# ESP32-H4 register map
Vendor: ESPRESSIF SYSTEMS (SHANGHAI) CO., LTD.; Series: ESP32 H-Series; File version: 1
CPU: RV32IMAC r0p0, little endian, no MPU, no FPU, 0 interrupt priority bits
Address unit: 32 bits
Registers are 32-bit, read-write, reset 0x0 unless marked. A register's access mark holds for its fields unless they carry their own. Offsets are from the block's base; [hi:lo] are bit positions; {n}, {i} and the like mark numbered series; <NAME> marks a mode.

## SPI2 — SPI (Serial Peripheral Interface) Controller 2
Base 0x60010000
Same registers: SPI3 0x60011000
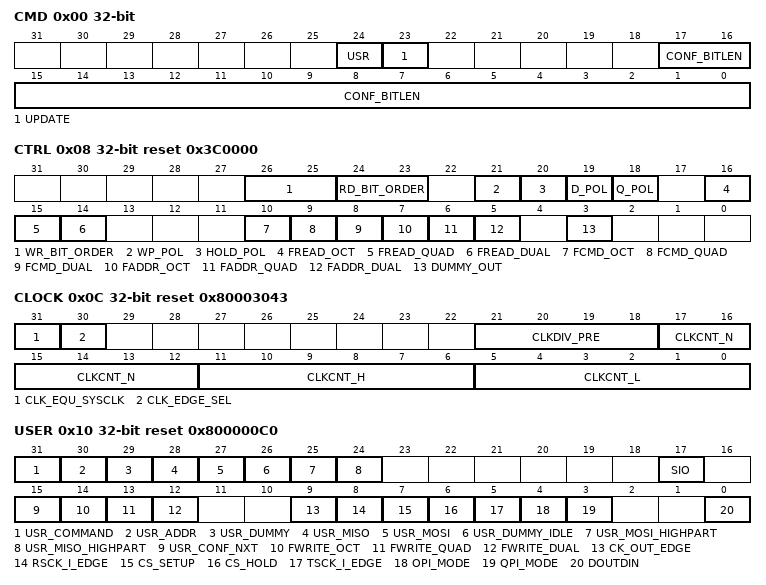
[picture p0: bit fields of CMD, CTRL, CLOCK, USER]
0x00 CMD — Command control register
  [24] USR — Configures whether or not to enable user-defined command. \\ 0: Not enable \\ 1: Enable \\ An SPI operation will be triggered when the bit is set. This bit will be cleared once the operation is done. Can not be changed by CONF_buf.
  [23] UPDATE — Configures whether or not to synchronize SPI registers from APB clock domain into SPI module clock domain. \\ 0: Not synchronize \\ 1: Synchronize \\ This bit is only used in SPI master transfer.
  [17:0] CONF_BITLEN — Configures the SPI_CLK cycles of SPI CONF state. Measurement unit: SPI_CLK clock cycle.\\ Can be configured in CONF state.
0x04 ADDR — Address value register
  [31:0] USR_ADDR_VALUE — Configures the address to slave. Can be configured in CONF state.
0x08 CTRL access per field reset 0x3C0000 — SPI control register
  [26:25] WR_BIT_ORDER rw — Configures the bit order in command (CMD), address (ADDR), and write-data (MOSI) states. \\ 0: MSB first \\ 1: LSB first \\ Can be configured in CONF state.
  [24:23] RD_BIT_ORDER rw — Configures the bit order in read-data (MISO) state. \\ 0: MSB first \\ 1: LSB first \\ Can be configured in CONF state.
  [21] WP_POL rw — Configures the output value of write-protect signal when SPI is in idle. \\ 0: Output low \\ 1: Output high \\ Can be configured in CONF state.
  [20] HOLD_POL rw — Configures SPI_HOLD output value when SPI is in idle. \\ 0: Output low \\ 1: Output high \\ Can be configured in CONF state.
  [19] D_POL rw — Configures MOSI line polarity. \\ 0: Low \\ 1: High \\ Can be configured in CONF state.
  [18] Q_POL rw — Configures MISO line polarity. \\ 0: Low \\ 1: High \\ Can be configured in CONF state.
  [16] FREAD_OCT ro — Configures whether or not to enable the 8-bit mode of read-data (DIN) state in read operations. \\ 0: Disable \\ 1: Enable \\ Can be configured in CONF state.
  [15] FREAD_QUAD rw — Configures whether or not to enable the 4-bit mode of read-data (DIN) state in read operations. \\ 0: Disable \\ 1: Enable \\ Can be configured in CONF state.
  [14] FREAD_DUAL rw — Configures whether or not to enable the 2-bit mode of read-data (DIN) state in read operations. \\ 0: Disable \\ 1: Enable \\ Can be configured in CONF state.
  [10] FCMD_OCT ro — Configures whether or not to enable 8-bit mode during command (CMD) state. \\ 0: Disable \\ 1: Enable \\ Can be configured in CONF state.
  [9] FCMD_QUAD rw — Configures whether or not to enable 4-bit mode during command (CMD) state. \\ 0: Disable \\ 1: Enable \\ Can be configured in CONF state.
  [8] FCMD_DUAL rw — Configures whether or not to enable 2-bit mode during command (CMD) state. \\ 0: Disable \\ 1: Enable \\ Can be configured in CONF state.
  [7] FADDR_OCT ro — Configures whether or not to enable 8-bit mode during address (ADDR) state. \\ 0: Disable \\ 1: Enable \\ Can be configured in CONF state.
  [6] FADDR_QUAD rw — Configures whether or not to enable 4-bit mode during address (ADDR) state. \\ 0: Disable \\ 1: Enable \\ Can be configured in CONF state.
  [5] FADDR_DUAL rw — Configures whether or not to enable 2-bit mode during address (ADDR) state.\\ 0: Disable \\ 1: Enable \\ Can be configured in CONF state.
  [3] DUMMY_OUT rw — Configures whether or not to output the FSPI bus signals in DUMMY state. \\ 0: Not output \\ 1: Output \\ Can be configured in CONF state.
0x0C CLOCK reset 0x80003043 — SPI clock control register
  [31] CLK_EQU_SYSCLK — Configures whether or not the SPI_CLK is equal to APB_CLK in master transfer.\\ 0: SPI_CLK is divided from APB_CLK.\\ 1: SPI_CLK is eqaul to APB_CLK.\\ Can be configured in CONF state.
  [30] CLK_EDGE_SEL — Configures use standard clock sampling edge or delay the sampling edge by half a cycle in master transfer.\\ 0: clock sampling edge is delayed by half a cycle.\\ 1: clock sampling edge is standard.\\ Can be configured in CONF state.
  [21:18] CLKDIV_PRE — Configures the pre-divider of SPI_CLK in master transfer. Can be configured in CONF state.
  [17:12] CLKCNT_N — Configures the divider of SPI_CLK in master transfer. SPI_CLK frequency is 12_{ extrm{apb_clk}}$/(SPI_CLKDIV_PRE + 1)/(SPI_CLKCNT_N + 1). \\ Can be configured in CONF state.
  [11:6] CLKCNT_H — Configures the duty cycle of SPI_CLK (high level) in master transfer. It's recommended to configure this value to floor((SPI_CLKCNT_N + 1)/2 - 1). floor() here is to round a number down, e.g., floor(2.2) = 2. In slave mode, it must be 0. \\ Can be configured in CONF state.
  [5:0] CLKCNT_L — In master transfer, this field must be equal to SPI_CLKCNT_N. In slave mode, it must be 0. Can be configured in CONF state.
0x10 USER access per field reset 0x800000C0 — SPI USER control register
  [31] USR_COMMAND rw — Configures whether or not to enable the command (CMD) state of an operation. \\ 0: Disable \\ 1: Enable \\ Can be configured in CONF state.
  [30] USR_ADDR rw — Configures whether or not to enable the address (ADDR) state of an operation. \\ 0: Disable \\ 1: Enable \\ Can be configured in CONF state.
  [29] USR_DUMMY rw — Configures whether or not to enable the DUMMY state of an operation. \\ 0: Disable \\ 1: Enable \\ Can be configured in CONF state.
  [28] USR_MISO rw — Configures whether or not to enable the read-data (DIN) state of an operation. \\ 0: Disable \\ 1: Enable \\ Can be configured in CONF state.
  [27] USR_MOSI rw — Configures whether or not to enable the write-data (DOUT) state of an operation. \\ 0: Disable \\ 1: Enable \\ Can be configured in CONF state.
  [26] USR_DUMMY_IDLE rw — Configures whether or not to disable SPI clock in DUMMY state. \\ 0: Not disable \\ 1: Disable \\ Can be configured in CONF state.
  [25] USR_MOSI_HIGHPART rw — Configures whether or not to enable high part mode, i.e., only access to high part of the buffers: SPI_W8_REG ~ SPI_W15_REG in write-data phase. \\ 0: Disable \\ 1: Enable \\ Can be configured in CONF state.
  [24] USR_MISO_HIGHPART rw — Configures whether or not to enable high part mode, i.e., only access to high part of the buffers: SPI_W8_REG ~ SPI_W15_REG in read-data phase. \\ 0: Disable \\ 1: Enable \\ Can be configured in CONF state.
  [17] SIO rw — Configures whether or not to enable 3-line half-duplex communication, where MOSI and MISO signals share the same pin.\\ 0: Disable \\ 1: Enable \\ Can be configured in CONF state.
  [15] USR_CONF_NXT rw — Configures whether or not to enable the CONF state for the next transaction (segment) in a configurable segmented transfer. \\ 0: this transfer will end after the current transaction (segment) is finished. Or this is not a configurable segmented transfer. \\ 1: this configurable segmented transfer will continue its next transaction (segment). \\ Can be configured in CONF state.
  [14] FWRITE_OCT ro — In the write operations read-data phase apply 8 signals. Can be configured in CONF state.
  [13] FWRITE_QUAD rw — Configures whether or not to enable the 4-bit mode of read-data phase in write operations. \\ 0: Not enable \\ 1: Enable \\ Can be configured in CONF state.
  [12] FWRITE_DUAL rw — Configures whether or not to enable the 2-bit mode of read-data phase in write operations.\\ 0: Not enable \\ 1: Enable \\ Can be configured in CONF state.
  [9] CK_OUT_EDGE rw — Configures SPI clock mode together with SPI_CK_IDLE_EDGE. Can be configured in CONF state. For more information, see Section <a href='GP-SPI2 master clock control'>link</a>.
  [8] RSCK_I_EDGE rw — Configures whether or not to change the polarity of RSCK in slave transfer. \\ 0: RSCK = !SPI_CK_I \\ 1: RSCK = SPI_CK_I \\
  [7] CS_SETUP rw — Configures whether or not to enable SPI CS when SPI is in prepare (PREP) state. \\ 0: Disable \\ 1: Enable \\ Can be configured in CONF state.
  [6] CS_HOLD rw — Configures whether or not to keep SPI CS low when SPI is in DONE state. \\ 0: Not keep low \\ 1: Keep low \\ Can be configured in CONF state.
  [5] TSCK_I_EDGE rw — Configures whether or not to change the polarity of TSCK in slave transfer. \\ 0: TSCK = SPI_CK_I \\ 1: TSCK = !SPI_CK_I \\
  [4] OPI_MODE ro — Just for master mode. 1: spi controller is in OPI mode (all in 8-b-m). 0: others. Can be configured in CONF state.
  [3] QPI_MODE rw — Configures whether or not to enable QPI mode. \\ 0: Disable \\ 1: Enable \\ This configuration is applicable when the SPI controller works as master or slave. Can be configured in CONF state.
  [0] DOUTDIN rw — Configures whether or not to enable full-duplex communication. \\ 0: Disable \\ 1: Enable \\ Can be configured in CONF state.
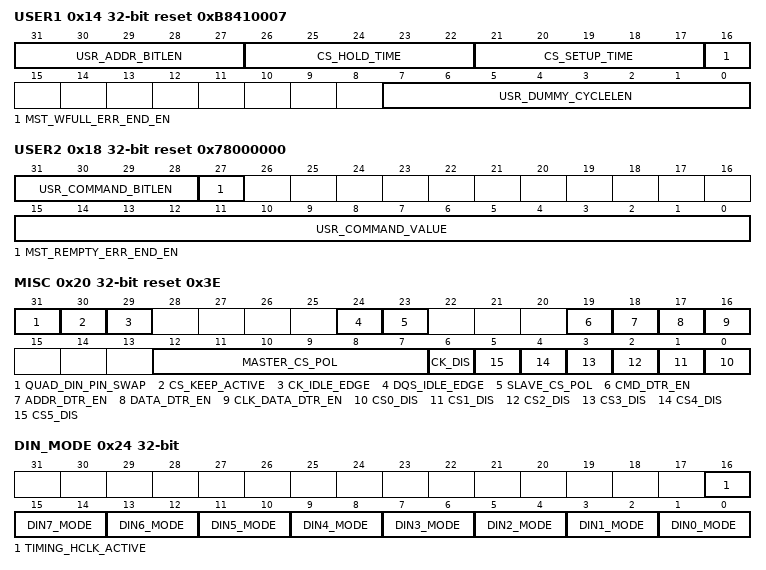
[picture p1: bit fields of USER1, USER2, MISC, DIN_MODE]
0x14 USER1 reset 0xB8410007 — SPI USER control register 1
  [31:27] USR_ADDR_BITLEN — Configures the bit length in address state. This value is (expected bit number - 1). Can be configured in CONF state.
  [26:22] CS_HOLD_TIME — Configures the delay cycles of CS pin. Measurement unit: SPI_CLK clock cycles. \\ This field is used together with SPI_CS_HOLD. Can be configured in CONF state.
  [21:17] CS_SETUP_TIME — Configures the length of prepare (PREP) state. Measurement unit: SPI_CLK clock cycles.\\ This value is equal to the expected cycles - 1. This field is used together with SPI_CS_SETUP. Can be configured in CONF state.
  [16] MST_WFULL_ERR_END_EN — Configures whether or not to end the SPI transfer when SPI RX AFIFO wfull error occurs in master full-/half-duplex transfers. \\ 0: Not end \\ 1: End \\
  [7:0] USR_DUMMY_CYCLELEN — Configures the length of DUMMY state. Measurement unit: SPI_CLK clock cycles.\\ This value is (the expected cycle number - 1). Can be configured in CONF state.
0x18 USER2 reset 0x78000000 — SPI USER control register 2
  [31:28] USR_COMMAND_BITLEN — Configures the bit length of command state. This value is (expected bit number - 1). Can be configured in CONF state.
  [27] MST_REMPTY_ERR_END_EN — Configures whether or not to end the SPI transfer when SPI TX AFIFO read empty error occurs in master full-/half-duplex transfers. \\ 0: Not end \\ 1: End \\
  [15:0] USR_COMMAND_VALUE — Configures the command value. Can be configured in CONF state.
0x1C MS_DLEN — SPI data bit length control register
  [17:0] MS_DATA_BITLEN — Configures the data bit length of SPI transfer in DMA-controlled master transfer or in CPU-controlled master transfer. Or configures the bit length of SPI RX transfer in DMA-controlled slave transfer. This value shall be (expected bit_num - 1). Can be configured in CONF state.
0x20 MISC access per field reset 0x3E — SPI misc register
  [31] QUAD_DIN_PIN_SWAP rw — 1: SPI quad input swap enable, swap FSPID with FSPIQ, swap FSPIWP with FSPIHD. 0: spi quad input swap disable. Can be configured in CONF state.
  [30] CS_KEEP_ACTIVE rw — Configures whether or not to keep the SPI_CS line low.\\ 0: Not keep low\\ 1: Keep low\\ Can be configured in CONF state.
  [29] CK_IDLE_EDGE rw — Configures the level of SPI_CLK line when GP-SPI2 is in idle.\\ 0: Low\\ 1: High\\ Can be configured in CONF state.
  [24] DQS_IDLE_EDGE ro — The default value of spi_dqs. Can be configured in CONF state.
  [23] SLAVE_CS_POL rw — Configures whether or not invert SPI slave input CS polarity.\\ 0: Not change\\ 1: Invert\\ Can be configured in CONF state.
  [19] CMD_DTR_EN ro — 1: SPI clk and data of SPI_SEND_CMD state are in DTR mode, including master 1/2/4/8-bm. 0: SPI clk and data of SPI_SEND_CMD state are in STR mode. Can be configured in CONF state.
  [18] ADDR_DTR_EN ro — 1: SPI clk and data of SPI_SEND_ADDR state are in DTR mode, including master 1/2/4/8-bm. 0: SPI clk and data of SPI_SEND_ADDR state are in STR mode. Can be configured in CONF state.
  [17] DATA_DTR_EN ro — 1: SPI clk and data of SPI_DOUT and SPI_DIN state are in DTR mode, including master 1/2/4/8-bm. 0: SPI clk and data of SPI_DOUT and SPI_DIN state are in STR mode. Can be configured in CONF state.
  [16] CLK_DATA_DTR_EN ro — 1: SPI master DTR mode is applied to SPI clk, data and spi_dqs. 0: SPI master DTR mode is only applied to spi_dqs. This bit should be used with bit 17/18/19.
  [12:7] MASTER_CS_POL rw — Configures the polarity of SPI_CS7 (7 = 0-5) line in master transfer.\\ 0: SPI_CS7 is low active.\\ 1: SPI_CS7 is high active.\\ Can be configured in CONF state.
  [6] CK_DIS rw — Configures whether or not to disable SPI_CLK output.\\ 0: Enable\\ 1: Disable\\ Can be configured in CONF state.
  [n] CS{n}_DIS rw (n=0..5) — Configures whether or not to disable SPI_CS{n} pin.\\ 0: SPI_CS{n} signal is from/to SPI_CS{n} pin.\\ 1: Disable SPI_CS{n} pin.\\ Can be configured in CONF state.
0x24 DIN_MODE access per field — SPI input delay mode configuration
  [16] TIMING_HCLK_ACTIVE rw — Configures whether or not to enable HCLK (high-frequency clock) in SPI input timing module.\\ 0: Disable\\ 1: Enable\\ Can be configured in CONF state.
  [2n+1:2n] DIN{n}_MODE ro (n=4..7) — the input signals are delayed by SPI module clock cycles, 0: input without delayed, 1: input with the posedge of clk_apb,2 input with the negedge of clk_apb, 3: input with the spi_clk. Can be configured in CONF state.
  [7:6] DIN3_MODE rw — Configures the input mode for FSPIHD signal.\\ 0: Input without delay\\ 1: Input at the (SPI_DIN3_NUM + 1)th falling edge of clk_spi_mst\\ 2: Input at the (SPI_DIN3_NUM + 1)th rising edge of clk_hclk plus one clk_spi_mst rising edge cycle\\ 3: Input at the (SPI_DIN3_NUM + 1)th rising edge of clk_hclk plus one clk_spi_mst falling edge cycle\\ Can be configured in CONF state.
  [5:4] DIN2_MODE rw — Configures the input mode for FSPIWP signal.\\ 0: Input without delay\\ 1: Input at the (SPI_DIN2_NUM + 1)th falling edge of clk_spi_mst\\ 2: Input at the (SPI_DIN2_NUM + 1)th rising edge of clk_hclk plus one clk_spi_mst rising edge cycle\\ 3: Input at the (SPI_DIN2_NUM + 1)th rising edge of clk_hclk plus one clk_spi_mst falling edge cycle\\ Can be configured in CONF state.
  [3:2] DIN1_MODE rw — Configures the input mode for FSPIQ signal.\\ 0: Input without delay\\ 1: Input at the (SPI_DIN1_NUM+1)th falling edge of clk_spi_mst\\ 2: Input at the (SPI_DIN1_NUM + 1)th rising edge of clk_hclk plus one clk_spi_mst rising edge cycle\\ 3: Input at the (SPI_DIN1_NUM + 1)th rising edge of clk_hclk plus one clk_spi_mst falling edge cycle\\ Can be configured in CONF state.
  [1:0] DIN0_MODE rw — Configures the input mode for FSPID signal.\\ 0: Input without delay\\ 1: Input at the (SPI_DIN0_NUM + 1)th falling edge of clk_spi_mst\\ 2: Input at the (SPI_DIN0_NUM + 1)th rising edge of clk_hclk plus one clk_spi_mst rising edge cycle\\ 3: Input at the (SPI_DIN0_NUM + 1)th rising edge of clk_hclk plus one clk_spi_mst falling edge cycle\\ Can be configured in CONF state.
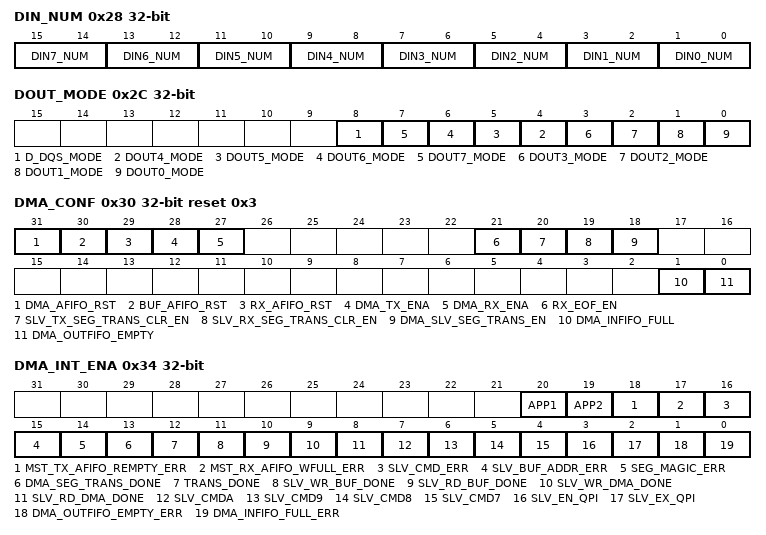
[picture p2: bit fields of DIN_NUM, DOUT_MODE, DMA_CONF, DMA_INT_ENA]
0x28 DIN_NUM access per field — SPI input delay number configuration
  [2n+1:2n] DIN{n}_NUM ro (n=4..7) — the input signals are delayed by SPI module clock cycles, 0: delayed by 1 cycle, 1: delayed by 2 cycles,... Can be configured in CONF state.
  [7:6] DIN3_NUM rw — Configures the delays to input signal FSPIHD based on the setting of SPI_DIN3_MODE.\\ 0: Delayed by 1 clock cycle\\ 1: Delayed by 2 clock cycles\\ 2: Delayed by 3 clock cycles\\ 3: Delayed by 4 clock cycles\\ Can be configured in CONF state.
  [5:4] DIN2_NUM rw — Configures the delays to input signal FSPIWP based on the setting of SPI_DIN2_MODE.\\ 0: Delayed by 1 clock cycle\\ 1: Delayed by 2 clock cycles\\ 2: Delayed by 3 clock cycles\\ 3: Delayed by 4 clock cycles\\ Can be configured in CONF state.
  [3:2] DIN1_NUM rw — Configures the delays to input signal FSPIQ based on the setting of SPI_DIN1_MODE.\\ 0: Delayed by 1 clock cycle\\ 1: Delayed by 2 clock cycles\\ 2: Delayed by 3 clock cycles\\ 3: Delayed by 4 clock cycles\\ Can be configured in CONF state.
  [1:0] DIN0_NUM rw — Configures the delays to input signal FSPID based on the setting of SPI_DIN0_MODE.\\ 0: Delayed by 1 clock cycle\\ 1: Delayed by 2 clock cycles\\ 2: Delayed by 3 clock cycles\\ 3: Delayed by 4 clock cycles\\ Can be configured in CONF state.
0x2C DOUT_MODE access per field — SPI output delay mode configuration
  [8] D_DQS_MODE ro — The output signal SPI_DQS is delayed by the SPI module clock, 0: output without delayed, 1: output delay for a SPI module clock cycle at its negative edge. Can be configured in CONF state.
  [n] DOUT{n}_MODE ro (n=4..7) — The output signal {n} is delayed by the SPI module clock, 0: output without delayed, 1: output delay for a SPI module clock cycle at its negative edge. Can be configured in CONF state.
  [3] DOUT3_MODE rw — Configures the output mode for FSPIHD signal.\\ 0: Output without delay\\ 1: Output with a delay of a SPI module clock cycle at its falling edge\\ Can be configured in CONF state.
  [2] DOUT2_MODE rw — Configures the output mode for FSPIWP signal.\\ 0: Output without delay\\ 1: Output with a delay of a SPI module clock cycle at its falling edge\\ Can be configured in CONF state.
  [1] DOUT1_MODE rw — Configures the output mode for FSPIQ signal.\\ 0: Output without delay\\ 1: Output with a delay of a SPI module clock cycle at its falling edge\\ Can be configured in CONF state.
  [0] DOUT0_MODE rw — Configures the output mode for FSPID signal.\\ 0: Output without delay\\ 1: Output with a delay of a SPI module clock cycle at its falling edge\\ Can be configured in CONF state.
0x30 DMA_CONF access per field reset 0x3 — SPI DMA control register
  [31] DMA_AFIFO_RST wo — Configures whether or not to reset dma_tx_afifo as shown in Figure <a href='fig:spi-master-data-flow-control'>link</a> and in Figure <a href='fig:spi-slave-data-flow-control'>link</a>.\\ 0: Not reset\\ 1: Reset\\ dma_tx_afifo is used to send data out in DMA-controlled slave transfer.
  [30] BUF_AFIFO_RST wo — Configures whether or not to reset buf_tx_afifo as shown in Figure <a href='fig:spi-master-data-flow-control'>link</a> and in Figure <a href='fig:spi-slave-data-flow-control'>link</a>.\\ 0: Not reset\\ 1: Reset\\ buf_tx_afifo is used to send data out in CPU-controlled master and slave transfer.
  [29] RX_AFIFO_RST wo — Configures whether or not to reset spi_rx_afifo as shown in Figure <a href='fig:spi-master-data-flow-control'>link</a> and in Figure <a href='fig:spi-slave-data-flow-control'>link</a>.\\ 0: Not reset\\ 1: Reset\\ spi_rx_afifo is used to receive data in SPI master and slave transfer.
  [28] DMA_TX_ENA rw — Configures whether or not to enable DMA-controlled send data transfer.\\ 0: Disable\\ 1: Enable\\
  [27] DMA_RX_ENA rw — Configures whether or not to enable DMA-controlled receive data transfer.\\ 0: Disable\\ 1: Enable\\
  [21] RX_EOF_EN rw — 1: In a DAM-controlled transfer, if the bit number of transferred data is equal to (SPI_MS_DATA_BITLEN + 1), then GDMA_IN_SUC_EOF_CH\it{n}_INT_RAW will be set by hardware. 0: GDMA_IN_SUC_EOF_CH\it{n}_INT_RAW is set by SPI_TRANS_DONE_INT event in a single transfer, or by an SPI_DMA_SEG_TRANS_DONE_INT event in a segmented transfer.
  [20] SLV_TX_SEG_TRANS_CLR_EN rw — In slave segmented transfer, if the size of the DMA TX buffer is smaller than the size of the transmitted data,\\ 1: the data in the following transactions will not be updated, i.e. the old data is transmitted repeatedly.\\ 0: the data in this transaction will not be updated. But in the following transactions,\\ - if new data is filled in DMA TX FIFO, new data will be transmitted. - if no new data is filled in DMA TX FIFO, no new data will be transmitted.
  [19] SLV_RX_SEG_TRANS_CLR_EN rw — In slave segmented transfer, if the size of the DMA RX buffer is smaller than the size of the received data, \\1: the data in all the following Wr_DMA transactions will not be received\\ 0: the data in this Wr_DMA transaction will not be received, but in the following transactions,\\ - if the size of DMA RX buffer is not 0, the data in following Wr_DMA transactions will be received. - if the size of DMA RX buffer is 0, the data in following Wr_DMA transactions will not be received.
  [18] DMA_SLV_SEG_TRANS_EN rw — Configures whether or not to enable DMA-controlled segmented transfer in slave half-duplex communication.\\ 0: Disable\\ 1: Enable\\
  [1] DMA_INFIFO_FULL ro — Represents whether or not the DMA RX FIFO is ready for receiving data.\\ 0: Ready\\ 1: Not ready\\
  [0] DMA_OUTFIFO_EMPTY ro — Represents whether or not the DMA TX FIFO is ready for sending data.\\ 0: Ready\\ 1: Not ready\\
0x34 DMA_INT_ENA — SPI interrupt enable register
  [20] APP1 — Write 1 to enable SPI_APP1_INT interrupt.
  [19] APP2 — Write 1 to enable SPI_APP2_INT interrupt.
  [18] MST_TX_AFIFO_REMPTY_ERR — Write 1 to enable SPI_MST_TX_AFIFO_REMPTY_ERR_INT interrupt.
  [17] MST_RX_AFIFO_WFULL_ERR — Write 1 to enable SPI_MST_RX_AFIFO_WFULL_ERR_INT interrupt.
  [16] SLV_CMD_ERR — Write 1 to enable SPI_SLV_CMD_ERR_INT interrupt.
  [15] SLV_BUF_ADDR_ERR — The enable bit for SPI_SLV_BUF_ADDR_ERR_INT interrupt.
  [14] SEG_MAGIC_ERR — Write 1 to enable SPI_SEG_MAGIC_ERR_INT interrupt.
  [13] DMA_SEG_TRANS_DONE — Write 1 to enable SPI_DMA_SEG_TRANS_DONE_INT interrupt.
  [12] TRANS_DONE — Write 1 to enable SPI_TRANS_DONE_INT interrupt.
  [11] SLV_WR_BUF_DONE — Write 1 to enable SPI_SLV_WR_BUF_DONE_INT interrupt.
  [10] SLV_RD_BUF_DONE — Write 1 to enable SPI_SLV_RD_BUF_DONE_INT interrupt.
  [9] SLV_WR_DMA_DONE — Write 1 to enable SPI_SLV_WR_DMA_DONE_INT interrupt.
  [8] SLV_RD_DMA_DONE — Write 1 to enable SPI_SLV_RD_DMA_DONE_INT interrupt.
  [7] SLV_CMDA — Write 1 to enable SPI_SLV_CMDA_INT interrupt.
  [6] SLV_CMD9 — Write 1 to enable SPI_SLV_CMD9_INT interrupt.
  [5] SLV_CMD8 — Write 1 to enable SPI_SLV_CMD8_INT interrupt.
  [4] SLV_CMD7 — Write 1 to enable SPI_SLV_CMD7_INT interrupt.
  [3] SLV_EN_QPI — Write 1 to enable SPI_SLV_EN_QPI_INT interrupt.
  [2] SLV_EX_QPI — Write 1 to enable SPI_SLV_EX_QPI_INT interrupt.
  [1] DMA_OUTFIFO_EMPTY_ERR — Write 1 to enable SPI_DMA_OUTFIFO_EMPTY_ERR_INT interrupt.
  [0] DMA_INFIFO_FULL_ERR — Write 1 to enable SPI_DMA_INFIFO_FULL_ERR_INT interrupt.
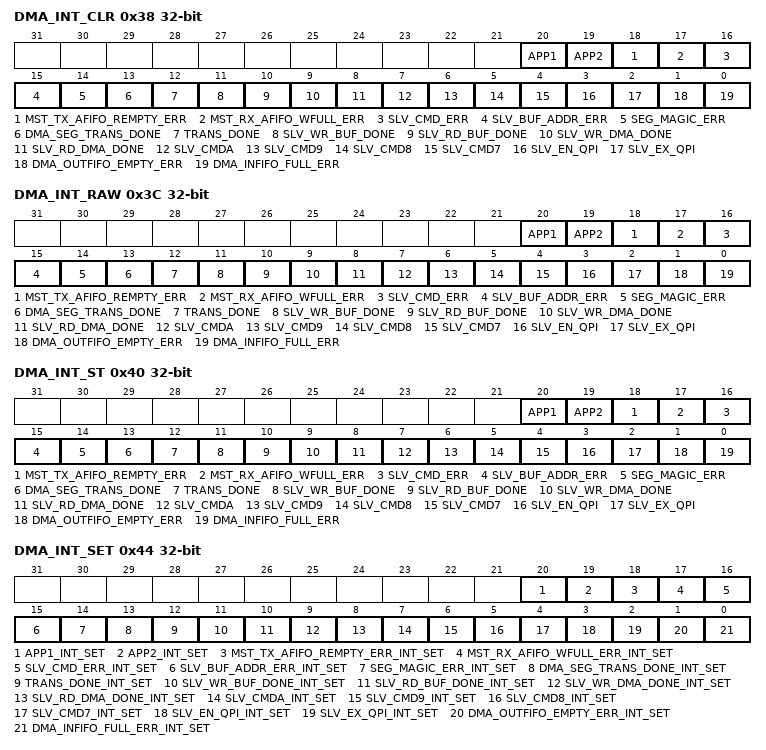
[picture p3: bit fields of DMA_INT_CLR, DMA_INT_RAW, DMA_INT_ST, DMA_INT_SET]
0x38 DMA_INT_CLR wo — SPI interrupt clear register
  [20] APP1 write-1-clears — Write 1 to clear SPI_APP1_INT interrupt.
  [19] APP2 write-1-clears — Write 1 to clear SPI_APP2_INT interrupt.
  [18] MST_TX_AFIFO_REMPTY_ERR write-1-clears — Write 1 to clear SPI_MST_TX_AFIFO_REMPTY_ERR_INT interrupt.
  [17] MST_RX_AFIFO_WFULL_ERR write-1-clears — Write 1 to clear SPI_MST_RX_AFIFO_WFULL_ERR_INT interrupt.
  [16] SLV_CMD_ERR write-1-clears — Write 1 to clear SPI_SLV_CMD_ERR_INT interrupt.
  [15] SLV_BUF_ADDR_ERR write-1-clears — The clear bit for SPI_SLV_BUF_ADDR_ERR_INT interrupt.
  [14] SEG_MAGIC_ERR write-1-clears — Write 1 to clear SPI_SEG_MAGIC_ERR_INT interrupt.
  [13] DMA_SEG_TRANS_DONE write-1-clears — Write 1 to clear SPI_DMA_SEG_TRANS_DONE_INT interrupt.
  [12] TRANS_DONE write-1-clears — Write 1 to clear SPI_TRANS_DONE_INT interrupt.
  [11] SLV_WR_BUF_DONE write-1-clears — Write 1 to clear SPI_SLV_WR_BUF_DONE_INT interrupt.
  [10] SLV_RD_BUF_DONE write-1-clears — Write 1 to clear SPI_SLV_RD_BUF_DONE_INT interrupt.
  [9] SLV_WR_DMA_DONE write-1-clears — Write 1 to clear SPI_SLV_WR_DMA_DONE_INT interrupt.
  [8] SLV_RD_DMA_DONE write-1-clears — Write 1 to clear SPI_SLV_RD_DMA_DONE_INT interrupt.
  [7] SLV_CMDA write-1-clears — Write 1 to clear SPI_SLV_CMDA_INT interrupt.
  [6] SLV_CMD9 write-1-clears — Write 1 to clear SPI_SLV_CMD9_INT interrupt.
  [5] SLV_CMD8 write-1-clears — Write 1 to clear SPI_SLV_CMD8_INT interrupt.
  [4] SLV_CMD7 write-1-clears — Write 1 to clear SPI_SLV_CMD7_INT interrupt.
  [3] SLV_EN_QPI write-1-clears — Write 1 to clear SPI_SLV_EN_QPI_INT interrupt.
  [2] SLV_EX_QPI write-1-clears — Write 1 to clear SPI_SLV_EX_QPI_INT interrupt.
  [1] DMA_OUTFIFO_EMPTY_ERR write-1-clears — Write 1 to clear SPI_DMA_OUTFIFO_EMPTY_ERR_INT interrupt.
  [0] DMA_INFIFO_FULL_ERR write-1-clears — Write 1 to clear SPI_DMA_INFIFO_FULL_ERR_INT interrupt.
0x3C DMA_INT_RAW — SPI interrupt raw register
  [20] APP1 — The raw interrupt status of SPI_APP1_INT interrupt. The value is only controlled by the application.
  [19] APP2 — The raw interrupt status of SPI_APP2_INT interrupt. The value is only controlled by the application.
  [18] MST_TX_AFIFO_REMPTY_ERR — The raw interrupt status of SPI_MST_TX_AFIFO_REMPTY_ERR_INT interrupt.
  [17] MST_RX_AFIFO_WFULL_ERR — The raw interrupt status of SPI_MST_RX_AFIFO_WFULL_ERR_INT interrupt.
  [16] SLV_CMD_ERR — The raw interrupt status of SPI_SLV_CMD_ERR_INT interrupt.
  [15] SLV_BUF_ADDR_ERR — The raw bit for SPI_SLV_BUF_ADDR_ERR_INT interrupt. 1: The accessing data address of the current SPI slave mode CPU controlled FD, Wr_BUF or Rd_BUF transmission is bigger than 63. 0: Others.
  [14] SEG_MAGIC_ERR — The raw interrupt status of SPI_SEG_MAGIC_ERR_INT interrupt.
  [13] DMA_SEG_TRANS_DONE — The raw interrupt status of SPI_DMA_SEG_TRANS_DONE_INT interrupt.
  [12] TRANS_DONE — The raw interrupt status of SPI_TRANS_DONE_INT interrupt.
  [11] SLV_WR_BUF_DONE — The raw interrupt status of SPI_SLV_WR_BUF_DONE_INT interrupt.
  [10] SLV_RD_BUF_DONE — The raw interrupt status of SPI_SLV_RD_BUF_DONE_INT interrupt.
  [9] SLV_WR_DMA_DONE — The raw interrupt status of SPI_SLV_WR_DMA_DONE_INT interrupt.
  [8] SLV_RD_DMA_DONE — The raw interrupt status of SPI_SLV_RD_DMA_DONE_INT interrupt.
  [7] SLV_CMDA — The raw interrupt status of SPI_SLV_CMDA_INT interrupt.
  [6] SLV_CMD9 — The raw interrupt status of SPI_SLV_CMD9_INT interrupt.
  [5] SLV_CMD8 — The raw interrupt status of SPI_SLV_CMD8_INT interrupt.
  [4] SLV_CMD7 — The raw interrupt status of SPI_SLV_CMD7_INT interrupt.
  [3] SLV_EN_QPI — The raw interrupt status of SPI_SLV_EN_QPI_INT interrupt.
  [2] SLV_EX_QPI — The raw interrupt status of SPI_SLV_EX_QPI_INT interrupt.
  [1] DMA_OUTFIFO_EMPTY_ERR — The raw interrupt status of SPI_DMA_OUTFIFO_EMPTY_ERR_INT interrupt.
  [0] DMA_INFIFO_FULL_ERR — The raw interrupt status of SPI_DMA_INFIFO_FULL_ERR_INT interrupt.
0x40 DMA_INT_ST ro — SPI interrupt status register
  [20] APP1 — The interrupt status of SPI_APP1_INT interrupt.
  [19] APP2 — The interrupt status of SPI_APP2_INT interrupt.
  [18] MST_TX_AFIFO_REMPTY_ERR — The interrupt status of SPI_MST_TX_AFIFO_REMPTY_ERR_INT interrupt.
  [17] MST_RX_AFIFO_WFULL_ERR — The interrupt status of SPI_MST_RX_AFIFO_WFULL_ERR_INT interrupt.
  [16] SLV_CMD_ERR — The interrupt status of SPI_SLV_CMD_ERR_INT interrupt.
  [15] SLV_BUF_ADDR_ERR — The status bit for SPI_SLV_BUF_ADDR_ERR_INT interrupt.
  [14] SEG_MAGIC_ERR — The interrupt status of SPI_SEG_MAGIC_ERR_INT interrupt.
  [13] DMA_SEG_TRANS_DONE — The interrupt status of SPI_DMA_SEG_TRANS_DONE_INT interrupt.
  [12] TRANS_DONE — The interrupt status of SPI_TRANS_DONE_INT interrupt.
  [11] SLV_WR_BUF_DONE — The interrupt status of SPI_SLV_WR_BUF_DONE_INT interrupt.
  [10] SLV_RD_BUF_DONE — The interrupt status of SPI_SLV_RD_BUF_DONE_INT interrupt.
  [9] SLV_WR_DMA_DONE — The interrupt status of SPI_SLV_WR_DMA_DONE_INT interrupt.
  [8] SLV_RD_DMA_DONE — The interrupt status of SPI_SLV_RD_DMA_DONE_INT interrupt.
  [7] SLV_CMDA — The interrupt status of SPI_SLV_CMDA_INT interrupt.
  [6] SLV_CMD9 — The interrupt status of SPI_SLV_CMD9_INT interrupt.
  [5] SLV_CMD8 — The interrupt status of SPI_SLV_CMD8_INT interrupt.
  [4] SLV_CMD7 — The interrupt status of SPI_SLV_CMD7_INT interrupt.
  [3] SLV_EN_QPI — The interrupt status of SPI_SLV_EN_QPI_INT interrupt.
  [2] SLV_EX_QPI — The interrupt status of SPI_SLV_EX_QPI_INT interrupt.
  [1] DMA_OUTFIFO_EMPTY_ERR — The interrupt status of SPI_DMA_OUTFIFO_EMPTY_ERR_INT interrupt.
  [0] DMA_INFIFO_FULL_ERR — The interrupt status of SPI_DMA_INFIFO_FULL_ERR_INT interrupt.
0x44 DMA_INT_SET wo — SPI interrupt software set register
  [20] APP1_INT_SET — Write 1 to set SPI_APP1_INT interrupt.
  [19] APP2_INT_SET — Write 1 to set SPI_APP2_INT interrupt.
  [18] MST_TX_AFIFO_REMPTY_ERR_INT_SET — Write 1 to set SPI_MST_TX_AFIFO_REMPTY_ERR_INT interrupt.
  [17] MST_RX_AFIFO_WFULL_ERR_INT_SET — Write 1 to set SPI_MST_RX_AFIFO_WFULL_ERR_INT interrupt.
  [16] SLV_CMD_ERR_INT_SET — Write 1 to set SPI_SLV_CMD_ERR_INT interrupt.
  [15] SLV_BUF_ADDR_ERR_INT_SET — The software set bit for SPI_SLV_BUF_ADDR_ERR_INT interrupt.
  [14] SEG_MAGIC_ERR_INT_SET — Write 1 to set SPI_SEG_MAGIC_ERR_INT interrupt.
  [13] DMA_SEG_TRANS_DONE_INT_SET — Write 1 to set SPI_DMA_SEG_TRANS_DONE_INT interrupt.
  [12] TRANS_DONE_INT_SET — Write 1 to set SPI_TRANS_DONE_INT interrupt.
  [11] SLV_WR_BUF_DONE_INT_SET — Write 1 to set SPI_SLV_WR_BUF_DONE_INT interrupt.
  [10] SLV_RD_BUF_DONE_INT_SET — Write 1 to set SPI_SLV_RD_BUF_DONE_INT interrupt.
  [9] SLV_WR_DMA_DONE_INT_SET — Write 1 to set SPI_SLV_WR_DMA_DONE_INT interrupt.
  [8] SLV_RD_DMA_DONE_INT_SET — Write 1 to set SPI_SLV_RD_DMA_DONE_INT interrupt.
  [7] SLV_CMDA_INT_SET — Write 1 to set SPI_SLV_CMDA_INT interrupt.
  [6] SLV_CMD9_INT_SET — Write 1 to set SPI_SLV_CMD9_INT interrupt.
  [5] SLV_CMD8_INT_SET — Write 1 to set SPI_SLV_CMD8_INT interrupt.
  [4] SLV_CMD7_INT_SET — Write 1 to set SPI_SLV_CMD7_INT interrupt.
  [3] SLV_EN_QPI_INT_SET — Write 1 to set SPI_SLV_EN_QPI_INT interrupt.
  [2] SLV_EX_QPI_INT_SET — Write 1 to set SPI_SLV_EX_QPI_INT interrupt.
  [1] DMA_OUTFIFO_EMPTY_ERR_INT_SET — Write 1 to set SPI_DMA_OUTFIFO_EMPTY_ERR_INT interrupt.
  [0] DMA_INFIFO_FULL_ERR_INT_SET — Write 1 to set SPI_DMA_INFIFO_FULL_ERR_INT interrupt.
{0x98+4i} W{i} (i=0..15) — SPI CPU-controlled buffer{i}
  [31:0] BUF — 32-bit data buffer 0.
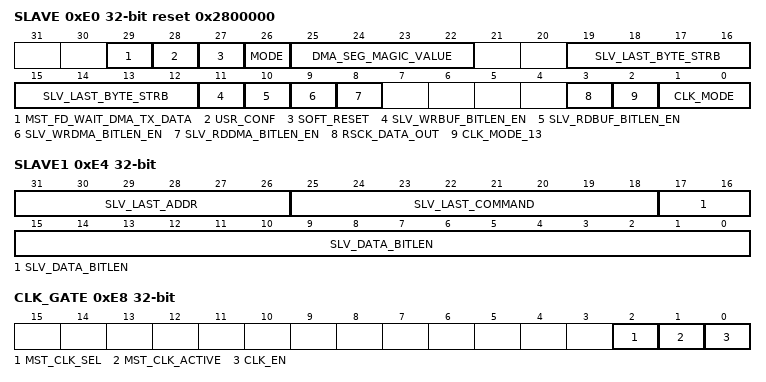
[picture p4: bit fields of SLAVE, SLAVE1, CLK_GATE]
0xE0 SLAVE access per field reset 0x2800000 — SPI slave control register
  [29] MST_FD_WAIT_DMA_TX_DATA rw — Configures whether or not to wait DMA TX data gets ready before starting SPI transfer in master full-duplex transfer.\\ 0: Not wait\\ 1: Wait\\
  [28] USR_CONF rw — Configures whether or not to enable the CONF state of current DMA-controlled configurable segmented transfer.\\ 0: No effect, which means the current transfer is not a configurable segmented transfer.\\ 1: Enable, which means a configurable segmented transfer is started.\\
  [27] SOFT_RESET wo — Configures whether to reset the SPI clock line, CS line, and data line via software.\\ 0: Not reset\\ 1: Reset\\ Can be configured in CONF state.
  [26] MODE rw — Configures SPI work mode.\\ 0: Master\\ 1: Slave\\
  [25:22] DMA_SEG_MAGIC_VALUE rw — Configures the magic value of BM table in DMA-controlled configurable segmented transfer.
  [19:12] SLV_LAST_BYTE_STRB ro — Represents the effective bit of the last received data byte in SPI slave FD and HD mode.
  [11] SLV_WRBUF_BITLEN_EN rw — Configures whether or not to use SPI_SLV_DATA_BITLEN to store the data bit length of Wr_BUF transfer.\\ 0: Not use\\ 1: Use\\
  [10] SLV_RDBUF_BITLEN_EN rw — Configures whether or not to use SPI_SLV_DATA_BITLEN to store the data bit length of Rd_BUF transfer.\\ 0: Not use\\ 1: Use\\
  [9] SLV_WRDMA_BITLEN_EN rw — Configures whether or not to use SPI_SLV_DATA_BITLEN to store the data bit length of Wr_DMA transfer.\\ 0: Not use\\ 1: Use\\
  [8] SLV_RDDMA_BITLEN_EN rw — Configures whether or not to use SPI_SLV_DATA_BITLEN to store the data bit length of Rd_DMA transfer.\\ 0: Not use\\ 1: Use\\
  [3] RSCK_DATA_OUT rw — Configures the edge of output data.\\ 0: Output data at TSCK rising edge.\\ 1: Output data at RSCK rising edge.\\
  [2] CLK_MODE_13 rw — Configure clock mode.\\ 0: Support SPI clock mode 0 or 2. See Table <a href='table:clock_pol_slave'>link</a>.\\ 1: Support SPI clock mode 1 or 3. See Table <a href='table:clock_pol_slave'>link</a>.\\
  [1:0] CLK_MODE rw — Configures SPI clock mode.\\ 0: SPI clock is off when CS becomes inactive.\\ 1: SPI clock is delayed one cycle after CS becomes inactive.\\ 2: SPI clock is delayed two cycles after CS becomes inactive.\\ 3: SPI clock is always on.\\ Can be configured in CONF state.
0xE4 SLAVE1 — SPI slave control register 1
  [31:26] SLV_LAST_ADDR — Configures the address value in slave mode.
  [25:18] SLV_LAST_COMMAND — Configures the command value in slave mode.
  [17:0] SLV_DATA_BITLEN — Configures the transferred data bit length in SPI slave full-/half-duplex modes.
0xE8 CLK_GATE — SPI module clock and register clock control
  [2] MST_CLK_SEL — This bit is used to select SPI module clock source in master mode. 1: PLL_CLK_80M. 0: XTAL CLK.
  [1] MST_CLK_ACTIVE — Set this bit to power on the SPI module clock.
  [0] CLK_EN — Configures whether or not to enable clock gate.\\ 0: Disable\\ 1: Enable\\
0xF0 DATE — Version control
